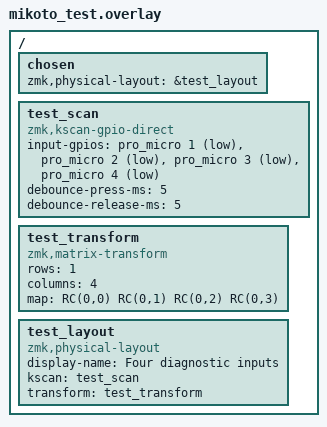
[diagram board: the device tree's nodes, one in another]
#include <dt-bindings/zmk/matrix_transform.h>

/ {
    chosen {
        zmk,physical-layout = &test_layout;
    };
    test_scan: test_scan {
        compatible = "zmk,kscan-gpio-direct";
        input-gpios = <&pro_micro 1 (GPIO_ACTIVE_LOW | GPIO_PULL_UP)>,
                      <&pro_micro 2 (GPIO_ACTIVE_LOW | GPIO_PULL_UP)>,
                      <&pro_micro 3 (GPIO_ACTIVE_LOW | GPIO_PULL_UP)>,
                      <&pro_micro 4 (GPIO_ACTIVE_LOW | GPIO_PULL_UP)>;
        debounce-press-ms = <5>;
        debounce-release-ms = <5>;
    };
    test_transform: test_transform {
        compatible = "zmk,matrix-transform";
        rows = <1>;
        columns = <4>;
        map = <RC(0,0) RC(0,1) RC(0,2) RC(0,3)>;
    };
    test_layout: test_layout {
        compatible = "zmk,physical-layout";
        display-name = "Four diagnostic inputs";
        kscan = <&test_scan>;
        transform = <&test_transform>;
    };
};
